VERSION "can_gui protocol 2"

NS_ :

BS_:

BU_: GUI MCU

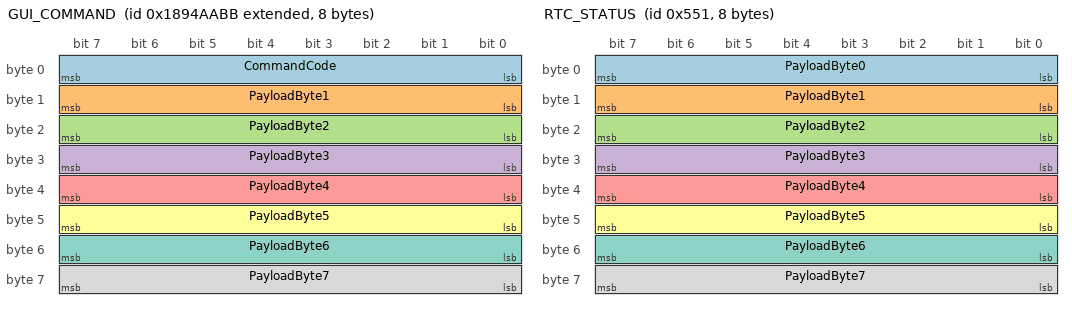
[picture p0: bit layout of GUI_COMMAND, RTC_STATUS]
BO_ 2559879867 GUI_COMMAND: 8 GUI
 SG_ CommandCode M : 0|8@1+ (1,0) [0|255] "" MCU
 SG_ PayloadByte1 : 8|8@1+ (1,0) [0|255] "" MCU
 SG_ PayloadByte2 : 16|8@1+ (1,0) [0|255] "" MCU
 SG_ PayloadByte3 : 24|8@1+ (1,0) [0|255] "" MCU
 SG_ PayloadByte4 : 32|8@1+ (1,0) [0|255] "" MCU
 SG_ PayloadByte5 : 40|8@1+ (1,0) [0|255] "" MCU
 SG_ PayloadByte6 : 48|8@1+ (1,0) [0|255] "" MCU
 SG_ PayloadByte7 : 56|8@1+ (1,0) [0|255] "" MCU

BO_ 1361 RTC_STATUS: 8 MCU
 SG_ PayloadByte0 : 0|8@1+ (1,0) [0|255] "" GUI
 SG_ PayloadByte1 : 8|8@1+ (1,0) [0|255] "" GUI
 SG_ PayloadByte2 : 16|8@1+ (1,0) [0|255] "" GUI
 SG_ PayloadByte3 : 24|8@1+ (1,0) [0|255] "" GUI
 SG_ PayloadByte4 : 32|8@1+ (1,0) [0|255] "" GUI
 SG_ PayloadByte5 : 40|8@1+ (1,0) [0|255] "" GUI
 SG_ PayloadByte6 : 48|8@1+ (1,0) [0|255] "" GUI
 SG_ PayloadByte7 : 56|8@1+ (1,0) [0|255] "" GUI

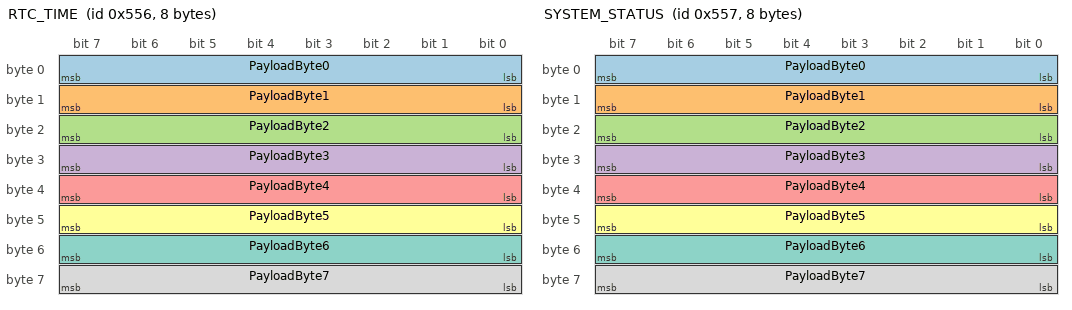
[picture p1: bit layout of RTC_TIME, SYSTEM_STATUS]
BO_ 1366 RTC_TIME: 8 MCU
 SG_ PayloadByte0 : 0|8@1+ (1,0) [0|255] "" GUI
 SG_ PayloadByte1 : 8|8@1+ (1,0) [0|255] "" GUI
 SG_ PayloadByte2 : 16|8@1+ (1,0) [0|255] "" GUI
 SG_ PayloadByte3 : 24|8@1+ (1,0) [0|255] "" GUI
 SG_ PayloadByte4 : 32|8@1+ (1,0) [0|255] "" GUI
 SG_ PayloadByte5 : 40|8@1+ (1,0) [0|255] "" GUI
 SG_ PayloadByte6 : 48|8@1+ (1,0) [0|255] "" GUI
 SG_ PayloadByte7 : 56|8@1+ (1,0) [0|255] "" GUI

BO_ 1367 SYSTEM_STATUS: 8 MCU
 SG_ PayloadByte0 : 0|8@1+ (1,0) [0|255] "" GUI
 SG_ PayloadByte1 : 8|8@1+ (1,0) [0|255] "" GUI
 SG_ PayloadByte2 : 16|8@1+ (1,0) [0|255] "" GUI
 SG_ PayloadByte3 : 24|8@1+ (1,0) [0|255] "" GUI
 SG_ PayloadByte4 : 32|8@1+ (1,0) [0|255] "" GUI
 SG_ PayloadByte5 : 40|8@1+ (1,0) [0|255] "" GUI
 SG_ PayloadByte6 : 48|8@1+ (1,0) [0|255] "" GUI
 SG_ PayloadByte7 : 56|8@1+ (1,0) [0|255] "" GUI

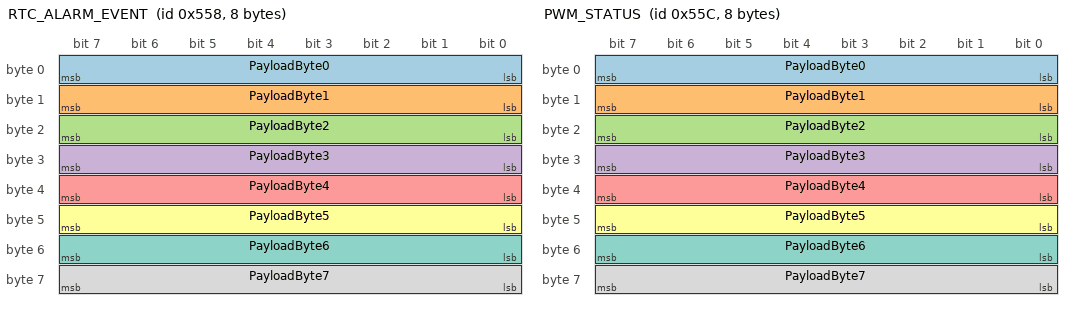
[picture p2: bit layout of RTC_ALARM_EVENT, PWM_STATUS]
BO_ 1368 RTC_ALARM_EVENT: 8 MCU
 SG_ PayloadByte0 : 0|8@1+ (1,0) [0|255] "" GUI
 SG_ PayloadByte1 : 8|8@1+ (1,0) [0|255] "" GUI
 SG_ PayloadByte2 : 16|8@1+ (1,0) [0|255] "" GUI
 SG_ PayloadByte3 : 24|8@1+ (1,0) [0|255] "" GUI
 SG_ PayloadByte4 : 32|8@1+ (1,0) [0|255] "" GUI
 SG_ PayloadByte5 : 40|8@1+ (1,0) [0|255] "" GUI
 SG_ PayloadByte6 : 48|8@1+ (1,0) [0|255] "" GUI
 SG_ PayloadByte7 : 56|8@1+ (1,0) [0|255] "" GUI

BO_ 1372 PWM_STATUS: 8 MCU
 SG_ PayloadByte0 : 0|8@1+ (1,0) [0|255] "" GUI
 SG_ PayloadByte1 : 8|8@1+ (1,0) [0|255] "" GUI
 SG_ PayloadByte2 : 16|8@1+ (1,0) [0|255] "" GUI
 SG_ PayloadByte3 : 24|8@1+ (1,0) [0|255] "" GUI
 SG_ PayloadByte4 : 32|8@1+ (1,0) [0|255] "" GUI
 SG_ PayloadByte5 : 40|8@1+ (1,0) [0|255] "" GUI
 SG_ PayloadByte6 : 48|8@1+ (1,0) [0|255] "" GUI
 SG_ PayloadByte7 : 56|8@1+ (1,0) [0|255] "" GUI

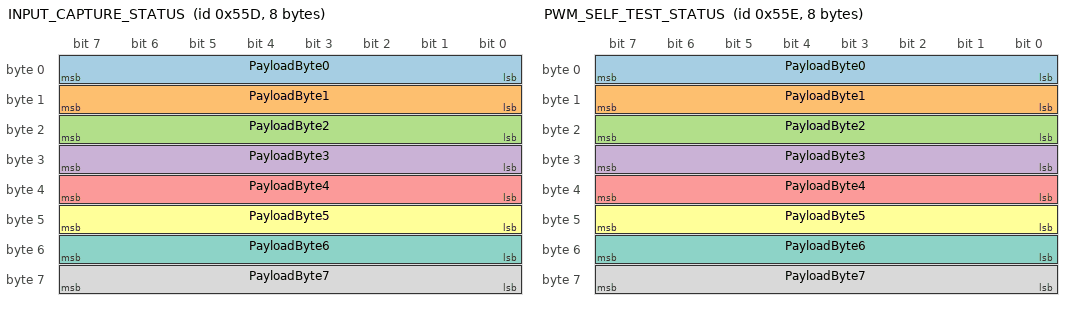
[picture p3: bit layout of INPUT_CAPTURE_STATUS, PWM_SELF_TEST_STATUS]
BO_ 1373 INPUT_CAPTURE_STATUS: 8 MCU
 SG_ PayloadByte0 : 0|8@1+ (1,0) [0|255] "" GUI
 SG_ PayloadByte1 : 8|8@1+ (1,0) [0|255] "" GUI
 SG_ PayloadByte2 : 16|8@1+ (1,0) [0|255] "" GUI
 SG_ PayloadByte3 : 24|8@1+ (1,0) [0|255] "" GUI
 SG_ PayloadByte4 : 32|8@1+ (1,0) [0|255] "" GUI
 SG_ PayloadByte5 : 40|8@1+ (1,0) [0|255] "" GUI
 SG_ PayloadByte6 : 48|8@1+ (1,0) [0|255] "" GUI
 SG_ PayloadByte7 : 56|8@1+ (1,0) [0|255] "" GUI

BO_ 1374 PWM_SELF_TEST_STATUS: 8 MCU
 SG_ PayloadByte0 : 0|8@1+ (1,0) [0|255] "" GUI
 SG_ PayloadByte1 : 8|8@1+ (1,0) [0|255] "" GUI
 SG_ PayloadByte2 : 16|8@1+ (1,0) [0|255] "" GUI
 SG_ PayloadByte3 : 24|8@1+ (1,0) [0|255] "" GUI
 SG_ PayloadByte4 : 32|8@1+ (1,0) [0|255] "" GUI
 SG_ PayloadByte5 : 40|8@1+ (1,0) [0|255] "" GUI
 SG_ PayloadByte6 : 48|8@1+ (1,0) [0|255] "" GUI
 SG_ PayloadByte7 : 56|8@1+ (1,0) [0|255] "" GUI

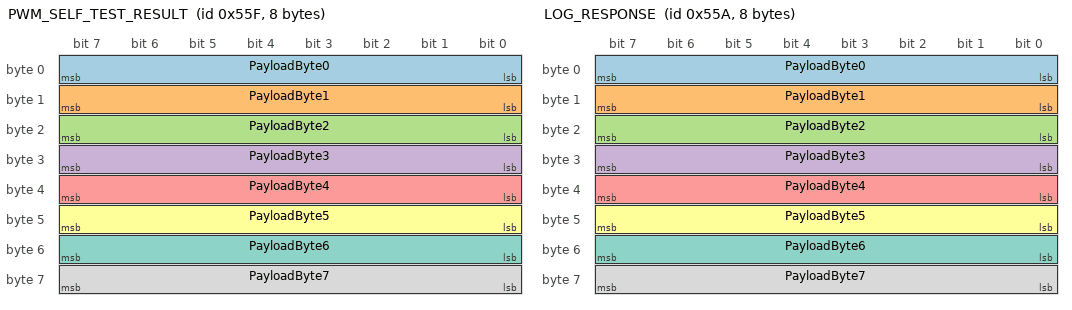
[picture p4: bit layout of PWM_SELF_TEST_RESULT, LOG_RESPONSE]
BO_ 1375 PWM_SELF_TEST_RESULT: 8 MCU
 SG_ PayloadByte0 : 0|8@1+ (1,0) [0|255] "" GUI
 SG_ PayloadByte1 : 8|8@1+ (1,0) [0|255] "" GUI
 SG_ PayloadByte2 : 16|8@1+ (1,0) [0|255] "" GUI
 SG_ PayloadByte3 : 24|8@1+ (1,0) [0|255] "" GUI
 SG_ PayloadByte4 : 32|8@1+ (1,0) [0|255] "" GUI
 SG_ PayloadByte5 : 40|8@1+ (1,0) [0|255] "" GUI
 SG_ PayloadByte6 : 48|8@1+ (1,0) [0|255] "" GUI
 SG_ PayloadByte7 : 56|8@1+ (1,0) [0|255] "" GUI

BO_ 1370 LOG_RESPONSE: 8 MCU
 SG_ PayloadByte0 : 0|8@1+ (1,0) [0|255] "" GUI
 SG_ PayloadByte1 : 8|8@1+ (1,0) [0|255] "" GUI
 SG_ PayloadByte2 : 16|8@1+ (1,0) [0|255] "" GUI
 SG_ PayloadByte3 : 24|8@1+ (1,0) [0|255] "" GUI
 SG_ PayloadByte4 : 32|8@1+ (1,0) [0|255] "" GUI
 SG_ PayloadByte5 : 40|8@1+ (1,0) [0|255] "" GUI
 SG_ PayloadByte6 : 48|8@1+ (1,0) [0|255] "" GUI
 SG_ PayloadByte7 : 56|8@1+ (1,0) [0|255] "" GUI

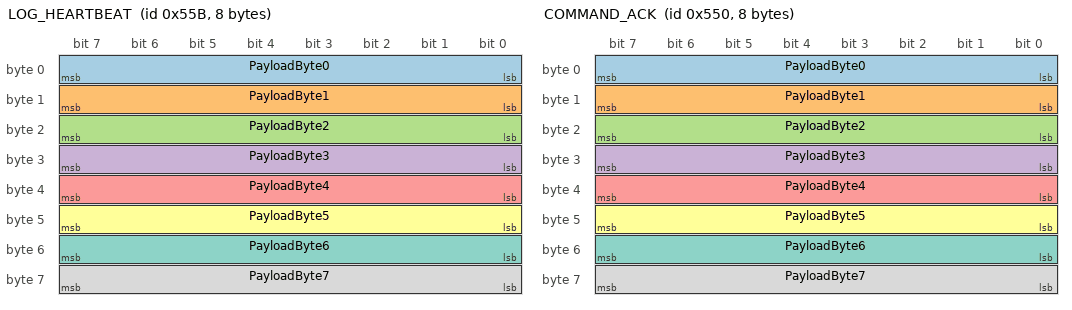
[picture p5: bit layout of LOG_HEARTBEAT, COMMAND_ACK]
BO_ 1371 LOG_HEARTBEAT: 8 MCU
 SG_ PayloadByte0 : 0|8@1+ (1,0) [0|255] "" GUI
 SG_ PayloadByte1 : 8|8@1+ (1,0) [0|255] "" GUI
 SG_ PayloadByte2 : 16|8@1+ (1,0) [0|255] "" GUI
 SG_ PayloadByte3 : 24|8@1+ (1,0) [0|255] "" GUI
 SG_ PayloadByte4 : 32|8@1+ (1,0) [0|255] "" GUI
 SG_ PayloadByte5 : 40|8@1+ (1,0) [0|255] "" GUI
 SG_ PayloadByte6 : 48|8@1+ (1,0) [0|255] "" GUI
 SG_ PayloadByte7 : 56|8@1+ (1,0) [0|255] "" GUI

BO_ 1360 COMMAND_ACK: 8 MCU
 SG_ PayloadByte0 : 0|8@1+ (1,0) [0|255] "" GUI
 SG_ PayloadByte1 : 8|8@1+ (1,0) [0|255] "" GUI
 SG_ PayloadByte2 : 16|8@1+ (1,0) [0|255] "" GUI
 SG_ PayloadByte3 : 24|8@1+ (1,0) [0|255] "" GUI
 SG_ PayloadByte4 : 32|8@1+ (1,0) [0|255] "" GUI
 SG_ PayloadByte5 : 40|8@1+ (1,0) [0|255] "" GUI
 SG_ PayloadByte6 : 48|8@1+ (1,0) [0|255] "" GUI
 SG_ PayloadByte7 : 56|8@1+ (1,0) [0|255] "" GUI

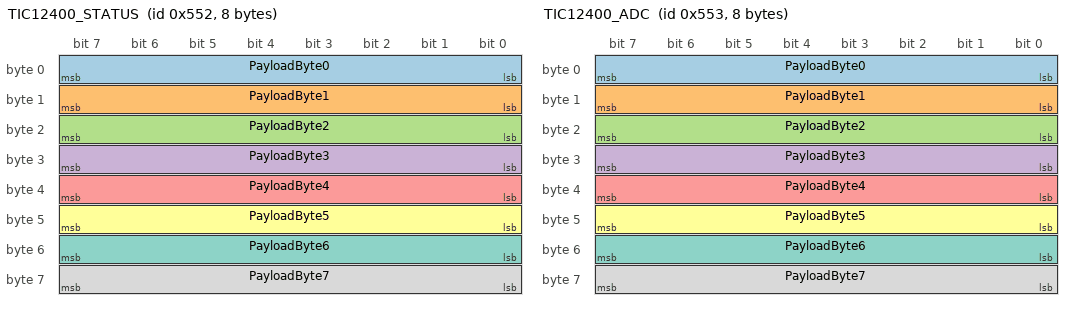
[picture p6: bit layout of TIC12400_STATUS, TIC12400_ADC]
BO_ 1362 TIC12400_STATUS: 8 MCU
 SG_ PayloadByte0 : 0|8@1+ (1,0) [0|255] "" GUI
 SG_ PayloadByte1 : 8|8@1+ (1,0) [0|255] "" GUI
 SG_ PayloadByte2 : 16|8@1+ (1,0) [0|255] "" GUI
 SG_ PayloadByte3 : 24|8@1+ (1,0) [0|255] "" GUI
 SG_ PayloadByte4 : 32|8@1+ (1,0) [0|255] "" GUI
 SG_ PayloadByte5 : 40|8@1+ (1,0) [0|255] "" GUI
 SG_ PayloadByte6 : 48|8@1+ (1,0) [0|255] "" GUI
 SG_ PayloadByte7 : 56|8@1+ (1,0) [0|255] "" GUI

BO_ 1363 TIC12400_ADC: 8 MCU
 SG_ PayloadByte0 : 0|8@1+ (1,0) [0|255] "" GUI
 SG_ PayloadByte1 : 8|8@1+ (1,0) [0|255] "" GUI
 SG_ PayloadByte2 : 16|8@1+ (1,0) [0|255] "" GUI
 SG_ PayloadByte3 : 24|8@1+ (1,0) [0|255] "" GUI
 SG_ PayloadByte4 : 32|8@1+ (1,0) [0|255] "" GUI
 SG_ PayloadByte5 : 40|8@1+ (1,0) [0|255] "" GUI
 SG_ PayloadByte6 : 48|8@1+ (1,0) [0|255] "" GUI
 SG_ PayloadByte7 : 56|8@1+ (1,0) [0|255] "" GUI

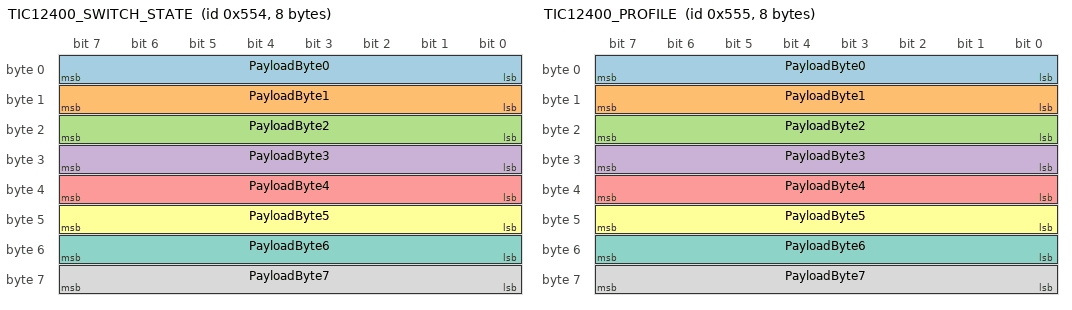
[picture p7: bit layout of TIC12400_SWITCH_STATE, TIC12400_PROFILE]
BO_ 1364 TIC12400_SWITCH_STATE: 8 MCU
 SG_ PayloadByte0 : 0|8@1+ (1,0) [0|255] "" GUI
 SG_ PayloadByte1 : 8|8@1+ (1,0) [0|255] "" GUI
 SG_ PayloadByte2 : 16|8@1+ (1,0) [0|255] "" GUI
 SG_ PayloadByte3 : 24|8@1+ (1,0) [0|255] "" GUI
 SG_ PayloadByte4 : 32|8@1+ (1,0) [0|255] "" GUI
 SG_ PayloadByte5 : 40|8@1+ (1,0) [0|255] "" GUI
 SG_ PayloadByte6 : 48|8@1+ (1,0) [0|255] "" GUI
 SG_ PayloadByte7 : 56|8@1+ (1,0) [0|255] "" GUI

BO_ 1365 TIC12400_PROFILE: 8 MCU
 SG_ PayloadByte0 : 0|8@1+ (1,0) [0|255] "" GUI
 SG_ PayloadByte1 : 8|8@1+ (1,0) [0|255] "" GUI
 SG_ PayloadByte2 : 16|8@1+ (1,0) [0|255] "" GUI
 SG_ PayloadByte3 : 24|8@1+ (1,0) [0|255] "" GUI
 SG_ PayloadByte4 : 32|8@1+ (1,0) [0|255] "" GUI
 SG_ PayloadByte5 : 40|8@1+ (1,0) [0|255] "" GUI
 SG_ PayloadByte6 : 48|8@1+ (1,0) [0|255] "" GUI
 SG_ PayloadByte7 : 56|8@1+ (1,0) [0|255] "" GUI

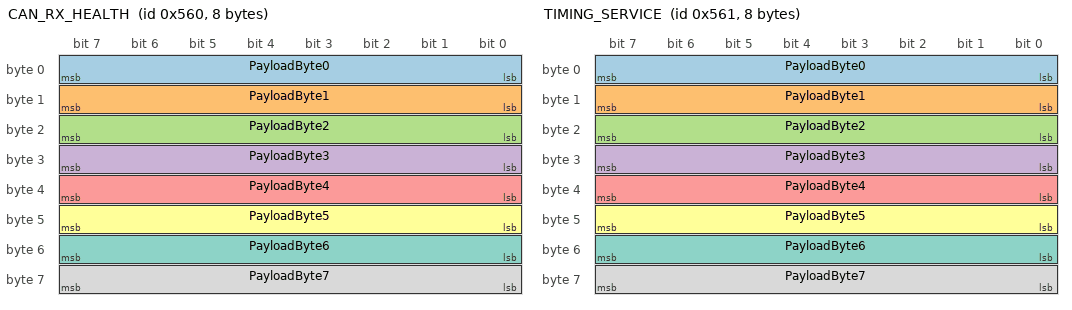
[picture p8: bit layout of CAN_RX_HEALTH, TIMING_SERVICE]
BO_ 1376 CAN_RX_HEALTH: 8 MCU
 SG_ PayloadByte0 : 0|8@1+ (1,0) [0|255] "" GUI
 SG_ PayloadByte1 : 8|8@1+ (1,0) [0|255] "" GUI
 SG_ PayloadByte2 : 16|8@1+ (1,0) [0|255] "" GUI
 SG_ PayloadByte3 : 24|8@1+ (1,0) [0|255] "" GUI
 SG_ PayloadByte4 : 32|8@1+ (1,0) [0|255] "" GUI
 SG_ PayloadByte5 : 40|8@1+ (1,0) [0|255] "" GUI
 SG_ PayloadByte6 : 48|8@1+ (1,0) [0|255] "" GUI
 SG_ PayloadByte7 : 56|8@1+ (1,0) [0|255] "" GUI

BO_ 1377 TIMING_SERVICE: 8 MCU
 SG_ PayloadByte0 : 0|8@1+ (1,0) [0|255] "" GUI
 SG_ PayloadByte1 : 8|8@1+ (1,0) [0|255] "" GUI
 SG_ PayloadByte2 : 16|8@1+ (1,0) [0|255] "" GUI
 SG_ PayloadByte3 : 24|8@1+ (1,0) [0|255] "" GUI
 SG_ PayloadByte4 : 32|8@1+ (1,0) [0|255] "" GUI
 SG_ PayloadByte5 : 40|8@1+ (1,0) [0|255] "" GUI
 SG_ PayloadByte6 : 48|8@1+ (1,0) [0|255] "" GUI
 SG_ PayloadByte7 : 56|8@1+ (1,0) [0|255] "" GUI

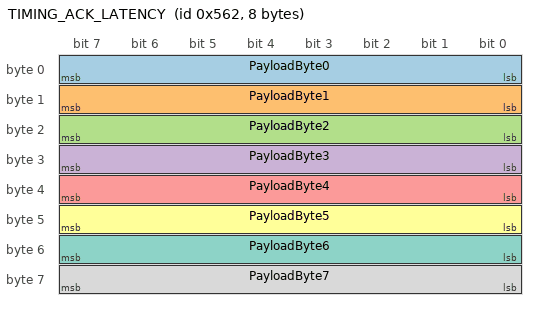
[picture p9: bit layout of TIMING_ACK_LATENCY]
BO_ 1378 TIMING_ACK_LATENCY: 8 MCU
 SG_ PayloadByte0 : 0|8@1+ (1,0) [0|255] "" GUI
 SG_ PayloadByte1 : 8|8@1+ (1,0) [0|255] "" GUI
 SG_ PayloadByte2 : 16|8@1+ (1,0) [0|255] "" GUI
 SG_ PayloadByte3 : 24|8@1+ (1,0) [0|255] "" GUI
 SG_ PayloadByte4 : 32|8@1+ (1,0) [0|255] "" GUI
 SG_ PayloadByte5 : 40|8@1+ (1,0) [0|255] "" GUI
 SG_ PayloadByte6 : 48|8@1+ (1,0) [0|255] "" GUI
 SG_ PayloadByte7 : 56|8@1+ (1,0) [0|255] "" GUI

CM_ BO_ 2559879867 "Fixed identifier for all multiplexed GUI commands";
CM_ BO_ 1361 "RTC operation status";
CM_ BO_ 1366 "RTC time and calendar";
CM_ BO_ 1367 "Slot and LED state";
CM_ BO_ 1368 "RTC alarm event notification";
CM_ BO_ 1372 "PWM output status";
CM_ BO_ 1373 "Input capture measurement with estimated edge count";
CM_ BO_ 1374 "PWM built-in self-test state and current target";
CM_ BO_ 1375 "PWM built-in self-test point result";
CM_ BO_ 1370 "STM32 event-log response fragments";
CM_ BO_ 1371 "STM32 event-log heartbeat";
CM_ BO_ 1360 "Command execution acknowledgement";
CM_ BO_ 1362 "TIC12400 device and service status";
CM_ BO_ 1363 "Segmented TIC12400 raw ADC snapshot";
CM_ BO_ 1364 "Debounced TIC12400 open/closed switch state";
CM_ BO_ 1365 "Applied TIC12400 switch-polarity profile";
CM_ BO_ 1376 "MCU FDCAN RX FIFO pressure and loss telemetry";
CM_ BO_ 1377 "DWT service execution timing telemetry";
CM_ BO_ 1378 "Command RX-to-ACK enqueue latency percentiles";

BA_DEF_ BO_ "VFrameFormat" ENUM "StandardCAN","ExtendedCAN";
BA_DEF_DEF_ "VFrameFormat" "StandardCAN";
BA_ "VFrameFormat" BO_ 2559879867 1;

VAL_ 2559879867 CommandCode 1 "SET_SLOT_1" 2 "SET_SLOT_2" 16 "LED_CONTROL" 17 "START_SLOT_1_COUNTER" 18 "START_SLOT_2_COUNTER" 32 "RTC_SET_TIME" 33 "RTC_SET_DATETIME" 34 "RTC_SET_ALARM" 64 "PWM_SET" 65 "PWM_SELF_TEST" 48 "LOG_GET_INFO" 49 "LOG_READ_SEQUENCE" 80 "TIC12400_SET_POLARITY" ;
